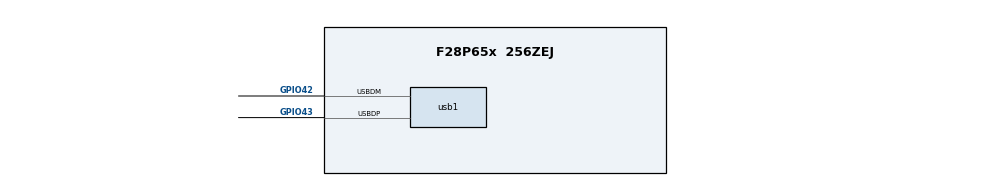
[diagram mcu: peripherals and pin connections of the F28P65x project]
/**
 * @cliArgs --device "F28P65x" --part "F28P65x_256ZEJ" --package "256ZEJ" --context "CPU1"
 * 
 */
/**
 * Import the modules used in this configuration.
 */
const usb  = scripting.addModule("/driverlib/usb.js", {}, false);
const usb1 = usb.addInstance();
/**
 * Write custom configuration values to the imported modules.
 */
usb1.$name                   = "myUSB0";
usb1.registerInterrupts      = true;
usb1.usb.$assign             = "USB0";
usb1.usb.usbdmPin.$assign   = "GPIO42";
usb1.usb.usbdpPin.$assign   = "GPIO43";
usb1.usbLib.usb_mode         = "Dual";
usb1.usbLib.deviceClasses    = "Mouse";
usb1.dmQual.$name            = "myGPIOQUAL0";
usb1.dpQual.$name            = "myGPIOQUAL1";
usb1.USBInt.enableInterrupt  = true;
usb1.USBInt.interruptHandler = "f28x_USB0DualModeIntHandler";
